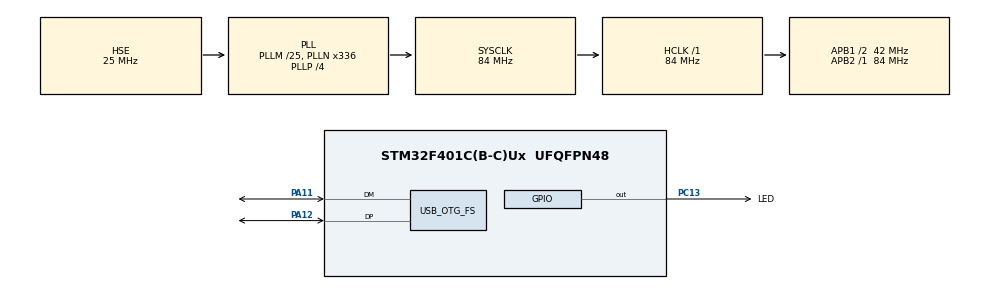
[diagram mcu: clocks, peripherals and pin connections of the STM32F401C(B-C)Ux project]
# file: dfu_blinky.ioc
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Mcu.Family=STM32F4
Mcu.Name=STM32F401C(B-C)Ux
Mcu.Package=UFQFPN48
NVIC.OTG_FS_IRQn=true\:0\:0\:false\:false\:true\:false\:true
NVIC.PriorityGroup=NVIC_PRIORITYGROUP_4
PA11.Mode=Device_Only
PA11.Signal=USB_OTG_FS_DM
PA12.Mode=Device_Only
PA12.Signal=USB_OTG_FS_DP
PC13-ANTI_TAMP.GPIO_Label=LED
PC13-ANTI_TAMP.Signal=GPIO_Output
PH0\ -\ OSC_IN.Mode=HSE-External-Oscillator
PH0\ -\ OSC_IN.Signal=RCC_OSC_IN
PH1\ -\ OSC_OUT.Mode=HSE-External-Oscillator
PH1\ -\ OSC_OUT.Signal=RCC_OSC_OUT
ProjectManager.HeapSize=0x200
ProjectManager.StackSize=0x400
ProjectManager.TargetToolchain=Makefile
RCC.48MHZClocksFreq_Value=48000000
RCC.AHBFreq_Value=84000000
RCC.APB1CLKDivider=RCC_HCLK_DIV2
RCC.APB1Freq_Value=42000000
RCC.APB1TimFreq_Value=84000000
RCC.APB2Freq_Value=84000000
RCC.APB2TimFreq_Value=84000000
RCC.CortexFreq_Value=84000000
RCC.HCLKFreq_Value=84000000
RCC.HSE_VALUE=25000000
RCC.HSI_VALUE=16000000
RCC.LSE_VALUE=32768
RCC.PLLM=25
RCC.PLLN=336
RCC.PLLP=RCC_PLLP_DIV4
RCC.PLLQ=7
RCC.SYSCLKFreq_VALUE=84000000
RCC.SYSCLKSource=RCC_SYSCLKSOURCE_PLLCLK
RCC.VCOOutputFreq_Value=336000000
USB_DEVICE.CLASS_NAME_FS=CDC
USB_DEVICE.MANUFACTURER_STRING=ZainsMicroelectronics
USB_DEVICE.PID_CDC_FS=0xABCD
USB_DEVICE.PRODUCT_STRING_CDC_FS=STM33
USB_DEVICE.VID=0xDEAD
USB_DEVICE.VirtualMode=Cdc
USB_DEVICE.VirtualModeFS=Cdc_FS
USB_OTG_FS.VirtualMode=Device_Only
VP_USB_DEVICE_VS_USB_DEVICE_CDC_FS.Mode=CDC_FS
board=custom

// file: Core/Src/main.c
/* USER CODE BEGIN Header */
/**
  ******************************************************************************
  * @file           : main.c
  * @brief          : Main program body
  ******************************************************************************
  * @attention
  *
  * <h2><center>&copy; Copyright (c) 2021 STMicroelectronics.
  * All rights reserved.</center></h2>
  *
  * This software component is licensed by ST under BSD 3-Clause license,
  * the "License"; You may not use this file except in compliance with the
  * License. You may obtain a copy of the License at:
  *                        opensource.org/licenses/BSD-3-Clause
  *
  ******************************************************************************
  */
/* USER CODE END Header */
#include "main.h"
#include "usb_device.h"
#include "gpio.h"

/* USER CODE BEGIN Includes */
#include "usbd_cdc_if.h"
#include "usbd_cdc.h"
#include <stdio.h>
#include <stdbool.h>
/* USER CODE END Includes */

/* USER CODE BEGIN PV */
bool should_reset = false;

/* USER CODE END PV */

void SystemClock_Config(void);

int main(void)
{

  /* MCU Configuration--------------------------------------------------------*/

  /* Reset of all peripherals, Initializes the Flash interface and the Systick. */
  HAL_Init();

  /* Configure the system clock */
  SystemClock_Config();

  /* Initialize all configured peripherals */
  MX_GPIO_Init();
  MX_USB_DEVICE_Init();

  /* Infinite loop */
  /* USER CODE BEGIN WHILE */
  static unsigned char buffer[64] = {0};
  static unsigned char msg[] = "Going down for reset\n";
  HAL_GPIO_WritePin(LED_GPIO_Port, LED_Pin, GPIO_PIN_RESET);
  while (1)
  {
    // Transmit the buffer minus the null terminator
    sprintf((char *)buffer, "uptime: %ld seconds\n", HAL_GetTick() / 1000);
    CDC_Transmit_FS(buffer, strlen((const char *)buffer));
    HAL_GPIO_TogglePin(LED_GPIO_Port, LED_Pin);
    HAL_Delay(1000);

    if (should_reset) {
      CDC_Transmit_FS(msg, sizeof(msg) - 1);
      for (uint32_t i = 0; i < 10; i++) {
        HAL_GPIO_TogglePin(LED_GPIO_Port, LED_Pin);
        HAL_Delay(100);
      }
      __NVIC_SystemReset();
    }
    /* USER CODE END WHILE */

  }
}

void SystemClock_Config(void)
{
  RCC_OscInitTypeDef RCC_OscInitStruct = {0};
  RCC_ClkInitTypeDef RCC_ClkInitStruct = {0};

  /** Configure the main internal regulator output voltage
  */
  __HAL_RCC_PWR_CLK_ENABLE();
  __HAL_PWR_VOLTAGESCALING_CONFIG(PWR_REGULATOR_VOLTAGE_SCALE2);
  /** Initializes the RCC Oscillators according to the specified parameters
  * in the RCC_OscInitTypeDef structure.
  */
  RCC_OscInitStruct.OscillatorType = RCC_OSCILLATORTYPE_HSE;
  RCC_OscInitStruct.HSEState = RCC_HSE_ON;
  RCC_OscInitStruct.PLL.PLLState = RCC_PLL_ON;
  RCC_OscInitStruct.PLL.PLLSource = RCC_PLLSOURCE_HSE;
  RCC_OscInitStruct.PLL.PLLM = 25;
  RCC_OscInitStruct.PLL.PLLN = 336;
  RCC_OscInitStruct.PLL.PLLP = RCC_PLLP_DIV4;
  RCC_OscInitStruct.PLL.PLLQ = 7;
  if (HAL_RCC_OscConfig(&RCC_OscInitStruct) != HAL_OK)
  {
    Error_Handler();
  }
  /** Initializes the CPU, AHB and APB buses clocks
  */
  RCC_ClkInitStruct.ClockType = RCC_CLOCKTYPE_HCLK|RCC_CLOCKTYPE_SYSCLK
                              |RCC_CLOCKTYPE_PCLK1|RCC_CLOCKTYPE_PCLK2;
  RCC_ClkInitStruct.SYSCLKSource = RCC_SYSCLKSOURCE_PLLCLK;
  RCC_ClkInitStruct.AHBCLKDivider = RCC_SYSCLK_DIV1;
  RCC_ClkInitStruct.APB1CLKDivider = RCC_HCLK_DIV2;
  RCC_ClkInitStruct.APB2CLKDivider = RCC_HCLK_DIV1;

  if (HAL_RCC_ClockConfig(&RCC_ClkInitStruct, FLASH_LATENCY_2) != HAL_OK)
  {
    Error_Handler();
  }
}

void Error_Handler(void)
{
  __disable_irq();
  while (1)
  {
  }
}

/************************ (C) COPYRIGHT STMicroelectronics *****END OF FILE****/
